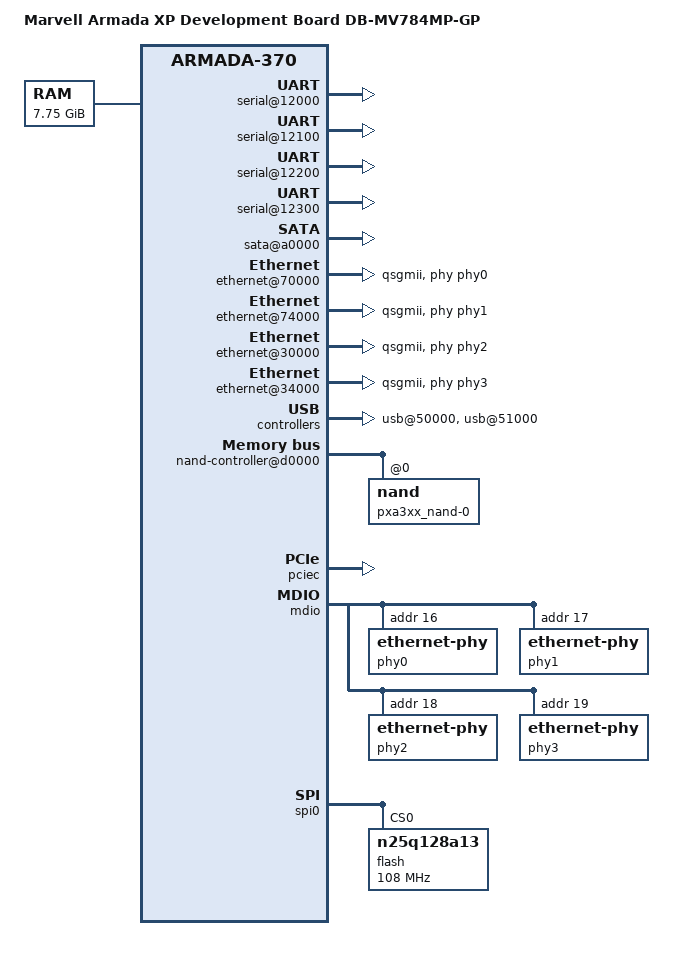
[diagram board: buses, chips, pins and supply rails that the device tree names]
/dts-v1/;
#include <dt-bindings/gpio/gpio.h>
#include "armada-xp-mv78460.dtsi"
/ {
	model = "Marvell Armada XP Development Board DB-MV784MP-GP";
	compatible = "marvell,axp-gp", "marvell,armadaxp-mv78460", "marvell,armadaxp", "marvell,armada-370-xp";
	chosen {
		stdout-path = "serial0:115200n8";
	};
	memory@0 {
		device_type = "memory";
		reg = <0x00000000 0x00000000 0x00000000 0xf0000000>,
		      <0x00000001 0x00000000 0x00000001 0x00000000>;
	};
	cpus {
		pm_pic {
			ctrl-gpios = <&gpio0 16 GPIO_ACTIVE_LOW>,
				     <&gpio0 17 GPIO_ACTIVE_LOW>,
				     <&gpio0 18 GPIO_ACTIVE_LOW>;
		};
	};
	soc {
		ranges = <MBUS_ID(0xf0, 0x01) 0 0 0xf1000000 0x100000
			  MBUS_ID(0x01, 0x1d) 0 0 0xfff00000 0x100000
			  MBUS_ID(0x01, 0x2f) 0 0 0xf0000000 0x1000000
			  MBUS_ID(0x09, 0x09) 0 0 0xf1100000 0x10000
			  MBUS_ID(0x09, 0x05) 0 0 0xf1110000 0x10000
			  MBUS_ID(0x0c, 0x04) 0 0 0xf1200000 0x100000>;
		devbus-bootcs {
			status = "okay";
			devbus,bus-width    = <16>;
			devbus,turn-off-ps  = <60000>;
			devbus,badr-skew-ps = <0>;
			devbus,acc-first-ps = <124000>;
			devbus,acc-next-ps  = <248000>;
			devbus,rd-setup-ps  = <0>;
			devbus,rd-hold-ps   = <0>;
			devbus,sync-enable = <0>;
			devbus,wr-high-ps  = <60000>;
			devbus,wr-low-ps   = <60000>;
			devbus,ale-wr-ps   = <60000>;
			nor@0 {
				compatible = "cfi-flash";
				reg = <0 0x1000000>;
				bank-width = <2>;
			};
		};
		internal-regs {
			serial@12000 {
				status = "okay";
			};
			serial@12100 {
				status = "okay";
			};
			serial@12200 {
				status = "okay";
			};
			serial@12300 {
				status = "okay";
			};
			pinctrl {
				pinctrl-0 = <&pic_pins>;
				pinctrl-names = "default";
				pic_pins: pic-pins-0 {
					marvell,pins = "mpp16", "mpp17",
						       "mpp18";
					marvell,function = "gpio";
				};
			};
			sata@a0000 {
				nr-ports = <2>;
				status = "okay";
			};
			ethernet@70000 {
				status = "okay";
				phy = <&phy0>;
				phy-mode = "qsgmii";
				buffer-manager = <&bm>;
				bm,pool-long = <0>;
			};
			ethernet@74000 {
				status = "okay";
				phy = <&phy1>;
				phy-mode = "qsgmii";
				buffer-manager = <&bm>;
				bm,pool-long = <1>;
			};
			ethernet@30000 {
				status = "okay";
				phy = <&phy2>;
				phy-mode = "qsgmii";
				buffer-manager = <&bm>;
				bm,pool-long = <2>;
			};
			ethernet@34000 {
				status = "okay";
				phy = <&phy3>;
				phy-mode = "qsgmii";
				buffer-manager = <&bm>;
				bm,pool-long = <3>;
			};
			usb@50000 {
				status = "okay";
			};
			usb@51000 {
				status = "okay";
			};
			bm@c0000 {
				status = "okay";
			};
			nand-controller@d0000 {
				status = "okay";
				nand@0 {
					reg = <0>;
					label = "pxa3xx_nand-0";
					nand-rb = <0>;
					nand-on-flash-bbt;
				};
			};
		};
		bm-bppi {
			status = "okay";
		};
	};
};
&pciec {
	status = "okay";
	pcie@1,0 {
		status = "okay";
	};
	pcie@9,0 {
		status = "okay";
	};
	pcie@a,0 {
		status = "okay";
	};
};
&mdio {
	phy0: ethernet-phy@0 {
		reg = <16>;
	};
	phy1: ethernet-phy@1 {
		reg = <17>;
	};
	phy2: ethernet-phy@2 {
		reg = <18>;
	};
	phy3: ethernet-phy@3 {
		reg = <19>;
	};
};
&spi0 {
	status = "okay";
	flash@0 {
		#address-cells = <1>;
		#size-cells = <1>;
		compatible = "n25q128a13", "jedec,spi-nor";
		reg = <0>;  
		spi-max-frequency = <108000000>;
	};
};
